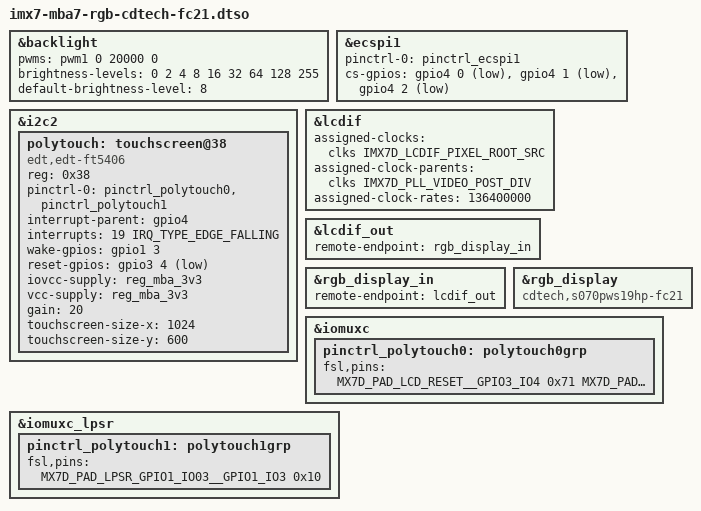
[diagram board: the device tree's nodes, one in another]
// SPDX-License-Identifier: (GPL-2.0-or-later OR MIT)
/*
 * Copyright (c) 2015-2024 TQ-Systems GmbH <linux@ew.tq-group.com>,
 * D-82229 Seefeld, Germany.
 * Author: Marco Felsch
 * Author: Markus Niebel
 * Author: Alexander Stein
 */

/dts-v1/;
/plugin/;

#include <dt-bindings/clock/imx7d-clock.h>
#include <dt-bindings/gpio/gpio.h>
#include <dt-bindings/interrupt-controller/irq.h>
#include "imx7d-pinfunc.h"

&backlight {
	pwms = <&pwm1 0 20000 0>;
	brightness-levels = <0 2 4 8 16 32 64 128 255>;
	default-brightness-level = <8>;
	status = "okay";
};

&ecspi1 {
	pinctrl-names = "default";
	/* SS0 is shared with touch IRQ, remove it here */
	pinctrl-0 = <&pinctrl_ecspi1>;
	cs-gpios = <&gpio4 0 GPIO_ACTIVE_LOW>, <&gpio4 1 GPIO_ACTIVE_LOW>,
		   <&gpio4 2 GPIO_ACTIVE_LOW>;
};

&i2c2 {
	#address-cells = <1>;
	#size-cells = <0>;

	polytouch: touchscreen@38 {
		compatible = "edt,edt-ft5406";
		reg = <0x38>;
		pinctrl-names = "default";
		pinctrl-0 = <&pinctrl_polytouch0 &pinctrl_polytouch1>;
		interrupt-parent = <&gpio4>;
		interrupts = <19 IRQ_TYPE_EDGE_FALLING>;
		wake-gpios = <&gpio1 3 GPIO_ACTIVE_HIGH>;
		reset-gpios = <&gpio3 4 GPIO_ACTIVE_LOW>;
		iovcc-supply = <&reg_mba_3v3>;
		vcc-supply = <&reg_mba_3v3>;
		gain = <20>;
		touchscreen-size-x = <1024>;
		touchscreen-size-y = <600>;
		status = "okay";
	};
};

&lcdif {
	assigned-clocks = <&clks IMX7D_LCDIF_PIXEL_ROOT_SRC>;
	assigned-clock-parents = <&clks IMX7D_PLL_VIDEO_POST_DIV>;
	assigned-clock-rates = <136400000>;
	status = "okay";
};

&lcdif_out {
	remote-endpoint = <&rgb_display_in>;
};

&rgb_display_in {
	remote-endpoint = <&lcdif_out>;
};

&rgb_display {
	compatible = "cdtech,s070pws19hp-fc21";
	status = "okay";
};

&iomuxc {
	pinctrl_polytouch0: polytouch0grp {
		fsl,pins = <
			MX7D_PAD_LCD_RESET__GPIO3_IO4		0x71
			MX7D_PAD_ECSPI1_SS0__GPIO4_IO19		0x7c
		>;
	};
};

&iomuxc_lpsr {
	pinctrl_polytouch1: polytouch1grp {
		fsl,pins = <
			MX7D_PAD_LPSR_GPIO1_IO03__GPIO1_IO3	0x10 /* LCD_PWR_EN */
		>;
	};
};
